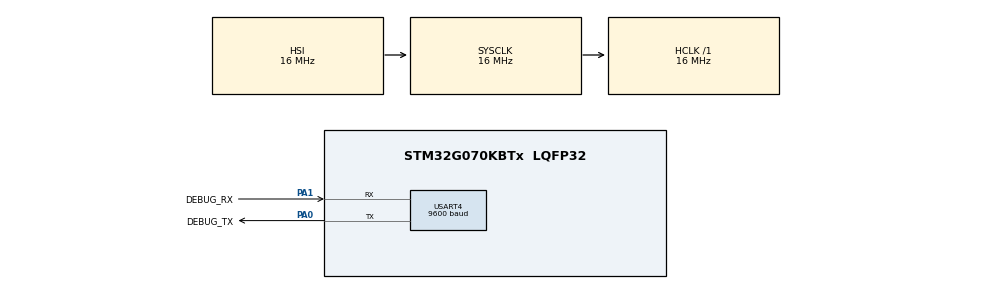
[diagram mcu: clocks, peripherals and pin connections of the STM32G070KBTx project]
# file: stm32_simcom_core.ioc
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Mcu.Family=STM32G0
Mcu.Name=STM32G070KBTx
Mcu.Package=LQFP32
NVIC.USART3_4_IRQn=true\:0\:0\:false\:false\:true\:true\:true\:true
PA0.GPIO_Label=DEBUG_TX
PA0.Mode=Asynchronous
PA0.Signal=USART4_TX
PA1.GPIO_Label=DEBUG_RX
PA1.Mode=Asynchronous
PA1.Signal=USART4_RX
PA13.Mode=Serial_Wire
PA13.Signal=SYS_SWDIO
PA14-BOOT0.Mode=Serial_Wire
PA14-BOOT0.Signal=SYS_SWCLK
ProjectManager.HeapSize=0x200
ProjectManager.StackSize=0x400
ProjectManager.TargetToolchain=STM32CubeIDE
RCC.AHBFreq_Value=16000000
RCC.CortexFreq_Value=16000000
RCC.EXTERNAL_CLOCK_VALUE=48000
RCC.HCLKFreq_Value=16000000
RCC.HSE_VALUE=8000000
RCC.HSI_VALUE=16000000
RCC.LSE_VALUE=32768
RCC.SYSCLKFreq_VALUE=16000000
RCC.VCOOutputFreq_Value=128000000
USART4.BaudRate=9600
USART4.VirtualMode-Asynchronous=VM_ASYNC
board=custom

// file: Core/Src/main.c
/* USER CODE BEGIN Header */
/**
  ******************************************************************************
  * @file           : main.c
  * @brief          : Main program body
  ******************************************************************************
  * @attention
  *
  * Copyright (c) 2024 STMicroelectronics.
  * All rights reserved.
  *
  * This software is licensed under terms that can be found in the LICENSE file
  * in the root directory of this software component.
  * If no LICENSE file comes with this software, it is provided AS-IS.
  *
  ******************************************************************************
  */
/* USER CODE END Header */
#include "main.h"

/* USER CODE BEGIN Includes */
#include "gsm.h"

/* USER CODE END Includes */

UART_HandleTypeDef huart4;
UART_HandleTypeDef* gsm_uart = &huart4; /* TODO change uart handle */
UART_HandleTypeDef* debug_uart = &huart4;

void SystemClock_Config(void);
static void MX_GPIO_Init(void);
static void MX_USART4_UART_Init(void);

/* USER CODE BEGIN 0 */
uint8_t gsm_uart_txbyte(uint8_t byte) {
	if(HAL_UART_Transmit(gsm_uart, &byte, 1, 500) == HAL_OK)
		return 1;
	return 0;
}
uint8_t gsm_uart_rxbyte(uint8_t* pbyte) {
	if(HAL_UART_Receive_IT(gsm_uart, (uint8_t*)pbyte, 1) == HAL_OK)
		return 1;
	return 0;
}

uint8_t gsm_debug_print(char* str) {
	char* p = str;
	while(*p != '\0') {
		if(HAL_UART_Transmit(debug_uart, (uint8_t*)p, 1, 10) != HAL_OK)
			return 0;
		p++;
	}
	return 1;
}
void gsm_delay(uint16_t t) {
	HAL_Delay(t);
}
uint8_t gsm_pwrkey(uint8_t set_reset) {
	/* TODO HAL_GPIO_Write */
}
uint8_t gsm_rst(uint8_t set_reset) {
	/* TODO HAL_GPIO_Write */
}

/* HAL callbacks */
void HAL_UART_RxCpltCallback(UART_HandleTypeDef* huart) {
	gsm_uart_rx_callback();
}
/* USER CODE END 0 */

int main(void)
{
a

  /* MCU Configuration--------------------------------------------------------*/

  /* Reset of all peripherals, Initializes the Flash interface and the Systick. */
  HAL_Init();

  /* Configure the system clock */
  SystemClock_Config();

  /* Initialize all configured peripherals */
  MX_GPIO_Init();
  MX_USART4_UART_Init();

  /* Infinite loop */
  /* USER CODE BEGIN WHILE */
  while (1)
  {
	  gsm_test();
    /* USER CODE END WHILE */

  }
}

void SystemClock_Config(void)
{
  RCC_OscInitTypeDef RCC_OscInitStruct = {0};
  RCC_ClkInitTypeDef RCC_ClkInitStruct = {0};

  /** Configure the main internal regulator output voltage
  */
  HAL_PWREx_ControlVoltageScaling(PWR_REGULATOR_VOLTAGE_SCALE1);

  /** Initializes the RCC Oscillators according to the specified parameters
  * in the RCC_OscInitTypeDef structure.
  */
  RCC_OscInitStruct.OscillatorType = RCC_OSCILLATORTYPE_HSI;
  RCC_OscInitStruct.HSIState = RCC_HSI_ON;
  RCC_OscInitStruct.HSIDiv = RCC_HSI_DIV1;
  RCC_OscInitStruct.HSICalibrationValue = RCC_HSICALIBRATION_DEFAULT;
  RCC_OscInitStruct.PLL.PLLState = RCC_PLL_NONE;
  if (HAL_RCC_OscConfig(&RCC_OscInitStruct) != HAL_OK)
  {
    Error_Handler();
  }

  /** Initializes the CPU, AHB and APB buses clocks
  */
  RCC_ClkInitStruct.ClockType = RCC_CLOCKTYPE_HCLK|RCC_CLOCKTYPE_SYSCLK
                              |RCC_CLOCKTYPE_PCLK1;
  RCC_ClkInitStruct.SYSCLKSource = RCC_SYSCLKSOURCE_HSI;
  RCC_ClkInitStruct.AHBCLKDivider = RCC_SYSCLK_DIV1;
  RCC_ClkInitStruct.APB1CLKDivider = RCC_HCLK_DIV1;

  if (HAL_RCC_ClockConfig(&RCC_ClkInitStruct, FLASH_LATENCY_0) != HAL_OK)
  {
    Error_Handler();
  }
}

static void MX_USART4_UART_Init(void)
{

  huart4.Instance = USART4;
  huart4.Init.BaudRate = 9600;
  huart4.Init.WordLength = UART_WORDLENGTH_8B;
  huart4.Init.StopBits = UART_STOPBITS_1;
  huart4.Init.Parity = UART_PARITY_NONE;
  huart4.Init.Mode = UART_MODE_TX_RX;
  huart4.Init.HwFlowCtl = UART_HWCONTROL_NONE;
  huart4.Init.OverSampling = UART_OVERSAMPLING_16;
  huart4.Init.OneBitSampling = UART_ONE_BIT_SAMPLE_DISABLE;
  huart4.Init.ClockPrescaler = UART_PRESCALER_DIV1;
  huart4.AdvancedInit.AdvFeatureInit = UART_ADVFEATURE_NO_INIT;
  if (HAL_UART_Init(&huart4) != HAL_OK)
  {
    Error_Handler();
  }

}

static void MX_GPIO_Init(void)
{

  /* GPIO Ports Clock Enable */
  __HAL_RCC_GPIOA_CLK_ENABLE();

}

void Error_Handler(void)
{
  __disable_irq();
  while (1)
  {
  }
}
